# psc3_p8_ppca register map
Vendor: Infineon Technologies; Series: PSC3_P8; File version: 1.0
CPU: CM33 r0p1, little endian, MPU, FPU, VTOR, 3 interrupt priority bits
Registers are 32-bit, read-write, reset 0x0 unless marked. A register's access mark holds for its fields unless they carry their own. Offsets are from the block's base; [hi:lo] are bit positions; lines under a group give offsets from that group; {n}, {i} and the like mark numbered series; 'fields as' and 'values as' point back to an identical list.

## PPCA_IPC — IPC
Base 0x43060000
{0x0+0x20*i} STRUCT[{i}] (i=0..3) group — IPC structure
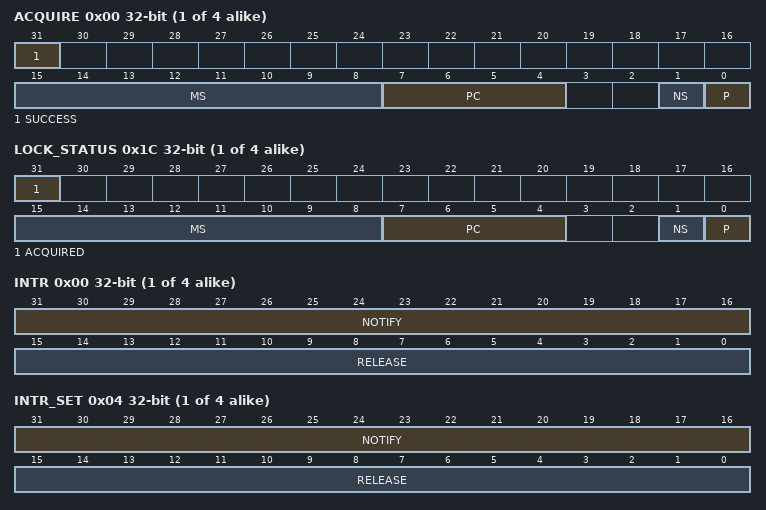
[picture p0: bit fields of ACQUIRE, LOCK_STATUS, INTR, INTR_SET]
  0x00 ACQUIRE ro (reset mask 0x80000000) — IPC acquire
    [31] SUCCESS
    [15:8] MS — This field specifies the bus master identifier that successfully acquired the lock.
    [7:4] PC
    [1] NS
    [0] P
  0x04 RELEASE wo — IPC release
    [15:0] INTR_RELEASE — Writing this field releases a lock and allows for the generation of release events to the IPC interrupt structures, but only when the lock is acquired (LOCK_STATUS.ACQUIRED is '1'). The IPC release cause fields associated with this IPC structure are set to '1', but only for those IPC interrupt structures for which the corresponding bit field in INTR_RELEASE[] is set to '1'. SW writes a '1' to the bit fields to generate a release event. Due to the transient nature of this event, SW always reads a '0' from this field.
  0x08 NOTIFY wo — IPC notification
    [15:0] INTR_NOTIFY — This field allows for the generation of notification events to the IPC interrupt structures. The IPC notification cause fields associated with this IPC structure are set to '1', but only for those IPC interrupt structures for which the corresponding bit field in INTR_NOTIFY[] is set to '1'. SW writes a '1' to the bit fields to generate a notify event. Due to the transient nature of this event, SW always reads a '0' from this field.
  0x0C DATA0 reset not defined — IPC data 0
    [31:0] DATA — This field holds a 32-bit data element that is associated with the IPC structure.
  0x10 DATA1 reset not defined — IPC data 1
    fields as STRUCT[0].DATA0
  0x1C LOCK_STATUS ro (reset mask 0x80000000) — IPC lock status
    [31] ACQUIRED
    [15:8] MS — This field specifies the bus master identifier that successfully acquired the lock.
    [7:4] PC
    [1] NS
    [0] P
{0x1000+0x20*i} INTR_STRUCT[{i}] (i=0..3) group — IPC interrupt structure
  0x00 INTR — Interrupt
    [31:16] NOTIFY — These interrupt cause fields are activated (HW sets the field to '1') when a IPC notification event is detected. One bit field for each master. SW writes a '1' to these field to clear the interrupt cause.
    [15:0] RELEASE — These interrupt cause fields are activated (HW sets the field to '1') when a IPC release event is detected. One bit field for each master. SW writes a '1' to these field to clear the interrupt cause.
  0x04 INTR_SET — Interrupt set
    [31:16] NOTIFY — SW writes a '1' to this field to set the corresponding field in the INTR register.
    [15:0] RELEASE — SW writes a '1' to this field to set the corresponding field in the INTR register.
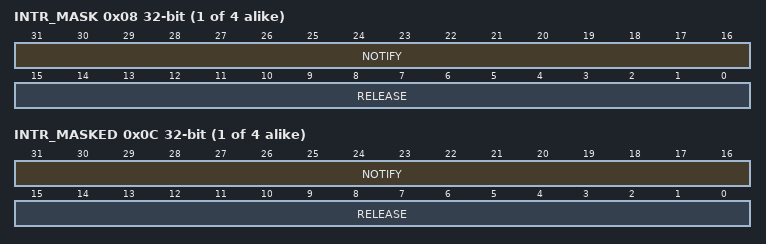
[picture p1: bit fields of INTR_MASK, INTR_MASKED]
  0x08 INTR_MASK — Interrupt mask
    [31:16] NOTIFY — Mask bit for corresponding field in the INTR register.
    [15:0] RELEASE — Mask bit for corresponding field in the INTR register.
  0x0C INTR_MASKED ro — Interrupt masked
    [31:16] NOTIFY — Logical and of corresponding INTR and INTR_MASK fields.
    [15:0] RELEASE — Logical and of corresponding request and mask bits.

## PPCA_HWFILT3P3Z_SS_0
Base 0x43500000
0x00 CTRL
  [31] HWFILT3P3Z_EN — HWFILT3P3Z_SS0 peripheral enable: 0 = disable (only mmio CTRL registers is accessible) 1 = enable (all AHB registers in the HWFILT3P3Z_SS0 are accessible)
{0x100+0x100*i} HWFILT3P3Z[{i}] (i=0..3) group
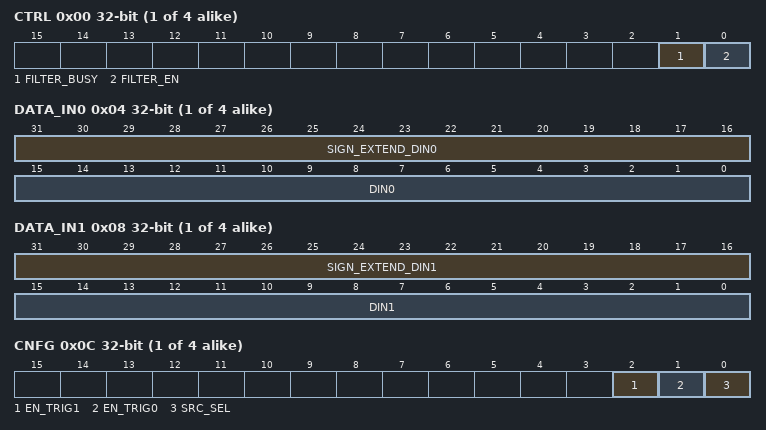
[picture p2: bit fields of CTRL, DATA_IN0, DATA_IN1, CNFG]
  0x00 CTRL
    [1] FILTER_BUSY ro — Filter output ready: 1 = busy 0 = free
    [0] FILTER_EN — Enable/Disable Filter: 0 = Disable (all registers are initilaized to the default values) 1 = Enable
  0x04 DATA_IN0
    [31:16] SIGN_EXTEND_DIN0 ro — Filter Data 0 Input Register sign extended
    [15:0] DIN0 — Filter Data 0 Input Register When writing, the filter processing will start if the corresponding trigger enable bit in the CNFG register is set
  0x08 DATA_IN1
    [31:16] SIGN_EXTEND_DIN1 ro — Filter Data 1 Input Register sign extended
    [15:0] DIN1 — Filter Data 1 Input Register When writing, the filter processing will start if the corresponding trigger enable bit in the CNFG register is set
  0x0C CNFG
    [2] EN_TRIG1 — Enable/Disable filter processing on writing into register DAT_IN1: 0 = Disable 1 = Enable
    [1] EN_TRIG0 — Enable/Disable filter processing on writing into register DAT_IN0: 0 = Disable 1 = Enable
    [0] SRC_SEL — Select source for register DATA_IN1: 0 = AHB IF 1 = DATA PATH
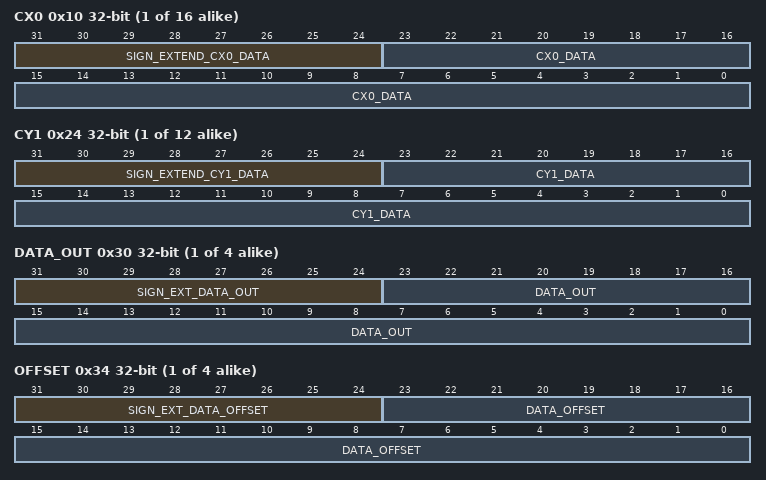
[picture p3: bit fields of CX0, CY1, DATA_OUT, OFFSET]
  {0x10+4j} CX{j} (j=0..3)
    [31:24] SIGN_EXTEND_CX{j}_DATA ro — Coefficient sign extended
    [23:0] CX{j}_DATA — Coefficient data register
  {0x20+4j} CY{j} (j=1..3)
    [31:24] SIGN_EXTEND_CY{j}_DATA ro — Coefficient sign extended
    [23:0] CY{j}_DATA — Coefficient data register
  0x30 DATA_OUT ro
    [31:24] SIGN_EXT_DATA_OUT — Filter Data Output Register sign extended
    [23:0] DATA_OUT — Filter Data Output Register
  0x34 OFFSET
    [31:24] SIGN_EXT_DATA_OFFSET ro — Filter Data Output Offset Register sign extended
    [23:0] DATA_OFFSET — Filter Data Output Offset Register
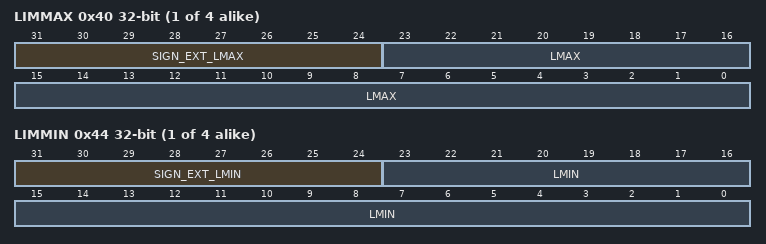
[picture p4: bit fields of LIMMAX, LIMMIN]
  0x40 LIMMAX
    [31:24] SIGN_EXT_LMAX ro — Filter Out Max Limit Register sign extended
    [23:0] LMAX — Filter Out Max Limit Register
  0x44 LIMMIN
    [31:24] SIGN_EXT_LMIN ro — Filter Out Min Limit Register sign extended
    [23:0] LMIN — Filter Out Min Limit Register
  0x60 SCALECX
    [2:0] SCALE_CX — Scale X Coefficients Factor
  0x64 SCALECY
    [2:0] SCALE_CY — Scale Y Coefficients Factor
  0x68 GIN
    [1:0] G_IN — Amplify input difference factor
  0x6C GOUT
    [2:0] G_OUT — Scale down output
  0x80 VERSION ro reset 0xC0DE0001
    [31:0] VERSION — Filter Version Register
